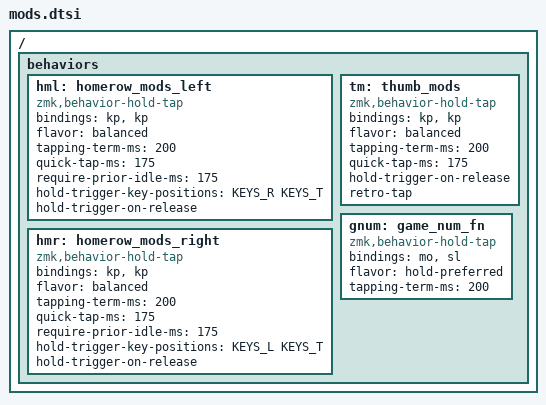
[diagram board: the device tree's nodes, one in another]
/ {
  behaviors {

    // Positional Homerow mods
    // Homerow mods that prevent accidental activations when rolling keys,
    // such as when typing `st` or `ne` on colemak-dh layouts or `as` on
    // qwerty.
    //
    // Works by only allowing a mod to activate within tapping-term if
    // it's on the opposite side of the keyboard or on the same side thumb
    // keys.

    // Further optimization using urob's timerless homerow mods method:
    // https://github.com/urob/zmk-config#timeless-homerow-mods
    hml: homerow_mods_left {
      compatible = "zmk,behavior-hold-tap";
      #binding-cells = <2>;
      bindings = <&kp>, <&kp>;

      flavor = "balanced";
      tapping-term-ms = <200>;
      quick-tap-ms = <175>;        // repeat on tap-into-hold
      require-prior-idle-ms = <175>; // was implied by deprecated `global-quick-tap`
      hold-trigger-key-positions = <KEYS_R KEYS_T>;
      hold-trigger-on-release;
    };

    hmr: homerow_mods_right {
      compatible = "zmk,behavior-hold-tap";
      #binding-cells = <2>;
      bindings = <&kp>, <&kp>;

      flavor = "balanced";
      tapping-term-ms = <200>;
      quick-tap-ms = <175>;
      require-prior-idle-ms = <175>; // was implied by deprecated `global-quick-tap`
      hold-trigger-key-positions = <KEYS_L KEYS_T>;
      hold-trigger-on-release;
    };

    tm: thumb_mods {
      compatible = "zmk,behavior-hold-tap";
      #binding-cells = <2>;
      bindings = <&kp>, <&kp>;

      flavor = "balanced";
      tapping-term-ms = <200>;
      quick-tap-ms = <175>;
      hold-trigger-on-release;
      retro-tap; // use tap when key is used without another key
    };

    // Game layer middle thumb: hold = momentary layer, tap = one-shot layer.
    // hold-preferred: pressing any key while held picks "hold" instantly,
    // so numbers have no added latency.
    gnum: game_num_fn {
      compatible = "zmk,behavior-hold-tap";
      #binding-cells = <2>;
      bindings = <&mo>, <&sl>;

      flavor = "hold-preferred";
      tapping-term-ms = <200>;
    };

  };
};
